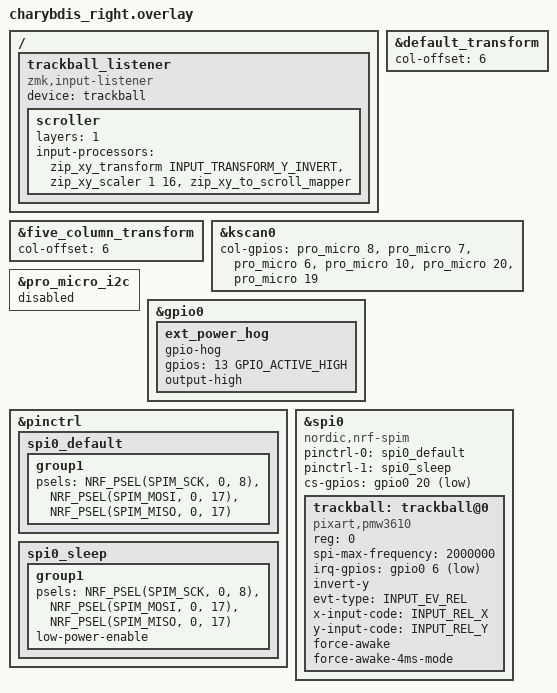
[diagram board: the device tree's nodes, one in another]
/*
 * Copyright (c) 2020 Pete Johanson
 *
 * SPDX-License-Identifier: MIT
 */

#include "charybdis.dtsi"
#include <zephyr/dt-bindings/input/input-event-codes.h>
#include <input/processors.dtsi>
#include <dt-bindings/zmk/input_transform.h>

&default_transform {
    col-offset = <6>;
};

&five_column_transform {
    col-offset = <6>;
};

&kscan0 {
    col-gpios
        = <&pro_micro 8 (GPIO_ACTIVE_HIGH | GPIO_PULL_DOWN)>
        , <&pro_micro 7 (GPIO_ACTIVE_HIGH | GPIO_PULL_DOWN)>
        , <&pro_micro 6 (GPIO_ACTIVE_HIGH | GPIO_PULL_DOWN)>
        , <&pro_micro 10 (GPIO_ACTIVE_HIGH | GPIO_PULL_DOWN)>
        , <&pro_micro 20 (GPIO_ACTIVE_HIGH | GPIO_PULL_DOWN)>
        , <&pro_micro 19 (GPIO_ACTIVE_HIGH | GPIO_PULL_DOWN)>
        ;
};

&pro_micro_i2c {
    status = "disabled";
};

&gpio0 {
    ext_power_hog {
        gpio-hog;
        gpios = <13 GPIO_ACTIVE_HIGH>;
        output-high;
    };
};

&pinctrl {
    spi0_default: spi0_default {
        group1 {
            psels = <NRF_PSEL(SPIM_SCK, 0, 8)>,
                    <NRF_PSEL(SPIM_MOSI, 0, 17)>,
                    <NRF_PSEL(SPIM_MISO, 0, 17)>;
        };
    };

    spi0_sleep: spi0_sleep {
        group1 {
            psels = <NRF_PSEL(SPIM_SCK, 0, 8)>,
                    <NRF_PSEL(SPIM_MOSI, 0, 17)>,
                    <NRF_PSEL(SPIM_MISO, 0, 17)>;
            low-power-enable;
        };
    };
};

&spi0 {
    status = "okay";
    compatible = "nordic,nrf-spim";
    pinctrl-0 = <&spi0_default>;
    pinctrl-1 = <&spi0_sleep>;
    pinctrl-names = "default", "sleep";
    cs-gpios = <&gpio0 20 GPIO_ACTIVE_LOW>;

    trackball: trackball@0 {
        status = "okay";
        compatible = "pixart,pmw3610";
        reg = <0>;
        spi-max-frequency = <2000000>;
        irq-gpios = <&gpio0 6 (GPIO_ACTIVE_LOW | GPIO_PULL_UP)>;
        invert-y;
        evt-type = <INPUT_EV_REL>;
        x-input-code = <INPUT_REL_X>;
        y-input-code = <INPUT_REL_Y>;
        force-awake;
        force-awake-4ms-mode;
    };
};

/ {
    /delete-node/ EXT_POWER;

    trackball_listener {
        compatible = "zmk,input-listener";
        device = <&trackball>;

        scroller {
            layers = <1>;
            input-processors = <&zip_xy_transform INPUT_TRANSFORM_Y_INVERT>,
                               <&zip_xy_scaler 1 16>,
                               <&zip_xy_to_scroll_mapper>;
        };
    };
};
